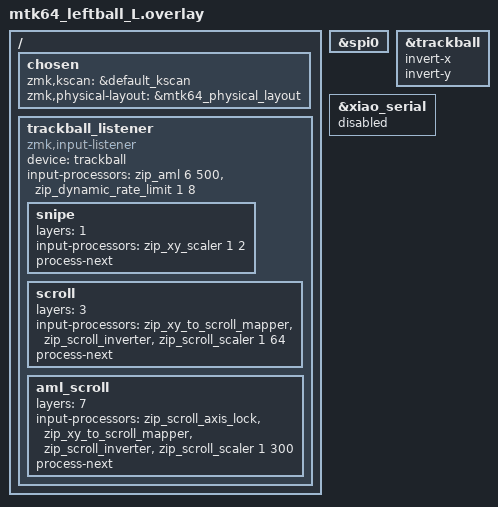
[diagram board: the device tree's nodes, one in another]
#include "mtk64.dtsi"
#include "mtk64_trackball.dtsi"

/ {
    chosen {
        zmk,kscan = &default_kscan;
        zmk,physical-layout = &mtk64_physical_layout;
    };
};

/ {
    trackball_listener: trackball_listener {
        compatible = "zmk,input-listener";
        status = "okay";
        device = <&trackball>;
        input-processors = <&zip_aml 6 500>, <&zip_dynamic_rate_limit 1 8>;

        snipe {
            layers = <1>;
            input-processors = <&zip_xy_scaler 1 2>;
            process-next;
        };

        scroll {
            layers = <3>;
            input-processors = <&zip_xy_to_scroll_mapper>, <&zip_scroll_inverter>, <&zip_scroll_scaler 1 64>;
            process-next;
        };

        // 自動マウスレイヤー中のスクロールキー (KC_MY_SCR 相当, &mo 7)
        // 元実装: 100 カウントで 1 ノッチ @500CPI -> 1558CPI で約 300
        aml_scroll {
            layers = <7>;
            input-processors = <&zip_scroll_axis_lock>, <&zip_xy_to_scroll_mapper>, <&zip_scroll_inverter>, <&zip_scroll_scaler 1 300>;
            process-next;
        };
    };
};

&spi0 {
    status = "okay";
};

&trackball { 
    status = "okay";
    invert-x;
    invert-y;
};

&xiao_serial { status = "disabled"; };

